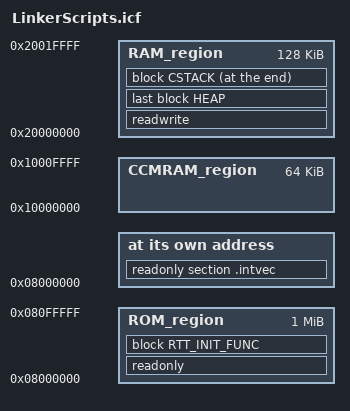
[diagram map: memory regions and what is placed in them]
/*###ICF### Section handled by ICF editor, don't touch! ****/
/*-Editor annotation file-*/
/* IcfEditorFile="$TOOLKIT_DIR$\config\ide\IcfEditor\cortex_v1_0.xml" */
/*-Specials-*/
define symbol __ICFEDIT_intvec_start__ = 0x08000000;
/*-Memory Regions-*/
define symbol __ICFEDIT_region_ROM_start__    = 0x08000000;
define symbol __ICFEDIT_region_ROM_end__      = 0x080FFFFF;
define symbol __ICFEDIT_region_RAM_start__    = 0x20000000;
define symbol __ICFEDIT_region_RAM_end__      = 0x2001FFFF;
define symbol __ICFEDIT_region_CCMRAM_start__ = 0x10000000;
define symbol __ICFEDIT_region_CCMRAM_end__   = 0x1000FFFF;
/*-Sizes-*/
define symbol __ICFEDIT_size_cstack__ = 0x2000;
define symbol __ICFEDIT_size_heap__   = 0x000;
/**** End of ICF editor section. ###ICF###*/


define memory mem with size = 4G;
define region ROM_region      = mem:[from __ICFEDIT_region_ROM_start__   to __ICFEDIT_region_ROM_end__];
define region RAM_region      = mem:[from __ICFEDIT_region_RAM_start__   to __ICFEDIT_region_RAM_end__];
define region CCMRAM_region   = mem:[from __ICFEDIT_region_CCMRAM_start__   to __ICFEDIT_region_CCMRAM_end__];

define block CSTACK    with alignment = 8, size = __ICFEDIT_size_cstack__   { };
define block HEAP      with alignment = 8, size = __ICFEDIT_size_heap__     { };

/* Keep RT-Thread initialization entries in level order. */
define block RTT_INIT_FUNC with fixed order { readonly section .rti_fn* };

initialize by copy { readwrite };
do not initialize  { section .noinit };

/* These tables are discovered through section boundaries at run time. */
keep { section FSymTab };
keep { section VSymTab };
keep { section RTMSymTab };
keep { section UtestTcTab };
keep { section .rti_fn* };

place at address mem:__ICFEDIT_intvec_start__ { readonly section .intvec };

place in ROM_region   { readonly, block RTT_INIT_FUNC };
/* The empty HEAP block marks the end of ordinary RW/ZI data. */
place in RAM_region   { readwrite, last block HEAP };
place at end of RAM_region { block CSTACK };
